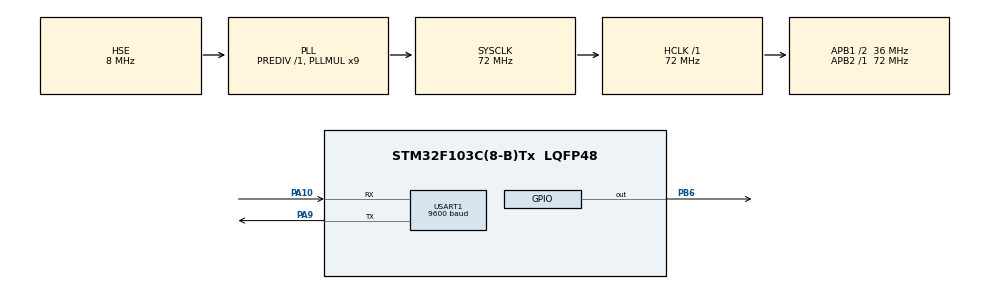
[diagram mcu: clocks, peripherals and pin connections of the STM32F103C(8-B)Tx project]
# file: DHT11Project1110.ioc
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Mcu.Family=STM32F1
Mcu.Name=STM32F103C(8-B)Tx
Mcu.Package=LQFP48
NVIC.PriorityGroup=NVIC_PRIORITYGROUP_4
PA10.Mode=Asynchronous
PA10.Signal=USART1_RX
PA9.Mode=Asynchronous
PA9.Signal=USART1_TX
PB6.GPIO_ModeDefaultOutputPP=GPIO_MODE_OUTPUT_OD
PB6.PinState=GPIO_PIN_SET
PB6.Signal=GPIO_Output
PD0-OSC_IN.Mode=HSE-External-Oscillator
PD0-OSC_IN.Signal=RCC_OSC_IN
PD1-OSC_OUT.Mode=HSE-External-Oscillator
PD1-OSC_OUT.Signal=RCC_OSC_OUT
ProjectManager.HeapSize=0x200
ProjectManager.StackSize=0x400
ProjectManager.TargetToolchain=STM32CubeIDE
RCC.AHBFreq_Value=72000000
RCC.APB1CLKDivider=RCC_HCLK_DIV2
RCC.APB1Freq_Value=36000000
RCC.APB1TimFreq_Value=72000000
RCC.APB2Freq_Value=72000000
RCC.APB2TimFreq_Value=72000000
RCC.HCLKFreq_Value=72000000
RCC.PLLMUL=RCC_PLL_MUL9
RCC.PLLSourceVirtual=RCC_PLLSOURCE_HSE
RCC.SYSCLKFreq_VALUE=72000000
RCC.SYSCLKSource=RCC_SYSCLKSOURCE_PLLCLK
RCC.USBFreq_Value=72000000
TIM1.Prescaler=71
USART1.BaudRate=9600
USART1.VirtualMode=VM_ASYNC
VP_SYS_VS_ND.Mode=No_Debug
VP_TIM1_VS_ClockSourceINT.Mode=Internal
board=custom

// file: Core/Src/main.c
/* USER CODE BEGIN Header */
/**
  ******************************************************************************
  * @file           : main.c
  * @brief          : Main program body
  ******************************************************************************
  * @attention
  *
  * <h2><center>&copy; Copyright (c) 2021 STMicroelectronics.
  * All rights reserved.</center></h2>
  *
  * This software component is licensed by ST under BSD 3-Clause license,
  * the "License"; You may not use this file except in compliance with the
  * License. You may obtain a copy of the License at:
  *                        opensource.org/licenses/BSD-3-Clause
  *
  ******************************************************************************
  */
/* USER CODE END Header */
#include "main.h"

/* USER CODE BEGIN Includes */
#include <stdio.h>
#include <string.h>
/* USER CODE END Includes */

TIM_HandleTypeDef htim1;

UART_HandleTypeDef huart1;

/* USER CODE BEGIN PV */
char error[12]={"Error 404!\n"};
char result[64]={0};
uint8_t i, j = 0;
uint8_t data[5] = {0, 0, 0, 0, 0};
uint16_t Hum1 = 0;
uint16_t Temp1 = 0;
uint8_t Width_neg = 0;
uint8_t Width_pos = 0;
/* USER CODE END PV */

void SystemClock_Config(void);
static void MX_GPIO_Init(void);
static void MX_USART1_UART_Init(void);
static void MX_TIM1_Init(void);

/* USER CODE BEGIN 0 */
static void goToOutput(void) { //Настройка порта на выход
	GPIO_InitTypeDef GPIO_InitStruct = {0};

  //По умолчанию на линии высокий уровень
	HAL_GPIO_WritePin(GPIOB, GPIO_PIN_6, GPIO_PIN_SET);

  //Настройка порта на выход
  GPIO_InitStruct.Pin = GPIO_PIN_6;
  GPIO_InitStruct.Mode = GPIO_MODE_OUTPUT_OD; 	//Открытый сток
  GPIO_InitStruct.Speed = GPIO_SPEED_FREQ_HIGH; //Высокая скорость работы порта
  HAL_GPIO_Init(GPIOB, &GPIO_InitStruct);
}

static void goToInput(void) {//Настройка порта на вход
  GPIO_InitTypeDef GPIO_InitStruct = {0};

  //Настройка порта на вход
  GPIO_InitStruct.Pin = GPIO_PIN_6;
  GPIO_InitStruct.Mode = GPIO_MODE_INPUT;
  HAL_GPIO_Init(GPIOB, &GPIO_InitStruct);
}

void delay (uint16_t time)
{
	TIM1 -> CNT = 0;//скидываем значение счетчика таймера
	while (TIM1 -> CNT < time);//считаем до time

}
/* USER CODE END 0 */

int main(void)
{

  /* MCU Configuration--------------------------------------------------------*/

  /* Reset of all peripherals, Initializes the Flash interface and the Systick. */
  HAL_Init();

  /* Configure the system clock */
  SystemClock_Config();

  /* Initialize all configured peripherals */
  MX_GPIO_Init();
  MX_USART1_UART_Init();
  MX_TIM1_Init();
  /* USER CODE BEGIN 2 */
  HAL_TIM_Base_Start(&htim1);
  /* USER CODE END 2 */

  /* Infinite loop */
  /* USER CODE BEGIN WHILE */
  while (1)
  {
	  goToOutput();
	  HAL_GPIO_WritePin(GPIOB, GPIO_PIN_6, GPIO_PIN_SET);
	  HAL_Delay(2000);
	  HAL_GPIO_WritePin(GPIOB, GPIO_PIN_6, GPIO_PIN_RESET);
	  delay(18000);// прижимаем сигнал на 18 мс
	  HAL_GPIO_WritePin(GPIOB, GPIO_PIN_6, GPIO_PIN_SET);
	  goToInput(); // переключаем порт на вход
	  delay(40);
	  if(HAL_GPIO_ReadPin(GPIOB, GPIO_PIN_6) == GPIO_PIN_RESET) //проверяем ответит ли датчик
	  {
		  delay(80);
		  if(HAL_GPIO_ReadPin(GPIOB, GPIO_PIN_6) == GPIO_PIN_SET)
		  	  {
			  delay(50);
			  	  for (j=0; j<5; j++) //начинаем считывать байты
			  	  {
			  		  data[4-j]=0;
			  		  for(i=0; i<8; i++)
			  		  {
			  			  while (HAL_GPIO_ReadPin(GPIOB, GPIO_PIN_6) == GPIO_PIN_RESET){
			  			  		  Width_neg++;
			  			  		  delay(1);}
			  			  while (HAL_GPIO_ReadPin(GPIOB, GPIO_PIN_6) == GPIO_PIN_SET){
			  			  		  Width_pos++;
			  			  		  delay(1);}
			  			  if (Width_pos > Width_neg) //Если длительность импульса положительной полярности больше чем длительность импульса отрицательной полярности то заносим 1
			  			  	  {
			  				  	  data[4-j] |= (1<<(7-i));
			  			  	  }
			  			  Width_neg = 0;
			  			  Width_pos = 0;
			  		  }
			  	  }
			  	  Hum1 = data[0];
			  	  Temp1 = data[2];
			  	  snprintf(result, 64, "Hum = %d %%,\n Temp = %d *C\n", Hum1, Temp1);
			  	  HAL_UART_Transmit(&huart1, (uint8_t*)result, strlen(result), 0xFF);
		  	  }
		  else
		  	  {
		  		  HAL_UART_Transmit(&huart1, (uint8_t*)error, strlen(error), 10);
		  	  }

	  }
	  else
	  {
		  HAL_UART_Transmit(&huart1, (uint8_t*)error, strlen(error), 10);
	  }
    /* USER CODE END WHILE */

  }
}

void SystemClock_Config(void)
{
  RCC_OscInitTypeDef RCC_OscInitStruct = {0};
  RCC_ClkInitTypeDef RCC_ClkInitStruct = {0};

  /** Initializes the RCC Oscillators according to the specified parameters
  * in the RCC_OscInitTypeDef structure.
  */
  RCC_OscInitStruct.OscillatorType = RCC_OSCILLATORTYPE_HSE;
  RCC_OscInitStruct.HSEState = RCC_HSE_ON;
  RCC_OscInitStruct.HSEPredivValue = RCC_HSE_PREDIV_DIV1;
  RCC_OscInitStruct.HSIState = RCC_HSI_ON;
  RCC_OscInitStruct.PLL.PLLState = RCC_PLL_ON;
  RCC_OscInitStruct.PLL.PLLSource = RCC_PLLSOURCE_HSE;
  RCC_OscInitStruct.PLL.PLLMUL = RCC_PLL_MUL9;
  if (HAL_RCC_OscConfig(&RCC_OscInitStruct) != HAL_OK)
  {
    Error_Handler();
  }
  /** Initializes the CPU, AHB and APB buses clocks
  */
  RCC_ClkInitStruct.ClockType = RCC_CLOCKTYPE_HCLK|RCC_CLOCKTYPE_SYSCLK
                              |RCC_CLOCKTYPE_PCLK1|RCC_CLOCKTYPE_PCLK2;
  RCC_ClkInitStruct.SYSCLKSource = RCC_SYSCLKSOURCE_PLLCLK;
  RCC_ClkInitStruct.AHBCLKDivider = RCC_SYSCLK_DIV1;
  RCC_ClkInitStruct.APB1CLKDivider = RCC_HCLK_DIV2;
  RCC_ClkInitStruct.APB2CLKDivider = RCC_HCLK_DIV1;

  if (HAL_RCC_ClockConfig(&RCC_ClkInitStruct, FLASH_LATENCY_2) != HAL_OK)
  {
    Error_Handler();
  }
}

static void MX_TIM1_Init(void)
{

  TIM_ClockConfigTypeDef sClockSourceConfig = {0};
  TIM_MasterConfigTypeDef sMasterConfig = {0};

  htim1.Instance = TIM1;
  htim1.Init.Prescaler = 71;
  htim1.Init.CounterMode = TIM_COUNTERMODE_UP;
  htim1.Init.Period = 65535;
  htim1.Init.ClockDivision = TIM_CLOCKDIVISION_DIV1;
  htim1.Init.RepetitionCounter = 0;
  htim1.Init.AutoReloadPreload = TIM_AUTORELOAD_PRELOAD_DISABLE;
  if (HAL_TIM_Base_Init(&htim1) != HAL_OK)
  {
    Error_Handler();
  }
  sClockSourceConfig.ClockSource = TIM_CLOCKSOURCE_INTERNAL;
  if (HAL_TIM_ConfigClockSource(&htim1, &sClockSourceConfig) != HAL_OK)
  {
    Error_Handler();
  }
  sMasterConfig.MasterOutputTrigger = TIM_TRGO_RESET;
  sMasterConfig.MasterSlaveMode = TIM_MASTERSLAVEMODE_DISABLE;
  if (HAL_TIMEx_MasterConfigSynchronization(&htim1, &sMasterConfig) != HAL_OK)
  {
    Error_Handler();
  }

}

static void MX_USART1_UART_Init(void)
{

  huart1.Instance = USART1;
  huart1.Init.BaudRate = 9600;
  huart1.Init.WordLength = UART_WORDLENGTH_8B;
  huart1.Init.StopBits = UART_STOPBITS_1;
  huart1.Init.Parity = UART_PARITY_NONE;
  huart1.Init.Mode = UART_MODE_TX_RX;
  huart1.Init.HwFlowCtl = UART_HWCONTROL_NONE;
  huart1.Init.OverSampling = UART_OVERSAMPLING_16;
  if (HAL_UART_Init(&huart1) != HAL_OK)
  {
    Error_Handler();
  }

}

static void MX_GPIO_Init(void)
{
  GPIO_InitTypeDef GPIO_InitStruct = {0};

  /* GPIO Ports Clock Enable */
  __HAL_RCC_GPIOD_CLK_ENABLE();
  __HAL_RCC_GPIOA_CLK_ENABLE();
  __HAL_RCC_GPIOB_CLK_ENABLE();

  /*Configure GPIO pin Output Level */
  HAL_GPIO_WritePin(GPIOB, GPIO_PIN_6, GPIO_PIN_SET);

  /*Configure GPIO pin : PB6 */
  GPIO_InitStruct.Pin = GPIO_PIN_6;
  GPIO_InitStruct.Mode = GPIO_MODE_OUTPUT_OD;
  GPIO_InitStruct.Pull = GPIO_NOPULL;
  GPIO_InitStruct.Speed = GPIO_SPEED_FREQ_LOW;
  HAL_GPIO_Init(GPIOB, &GPIO_InitStruct);

}

void Error_Handler(void)
{
  __disable_irq();
  while (1)
  {
  }
}

/************************ (C) COPYRIGHT STMicroelectronics *****END OF FILE****/
